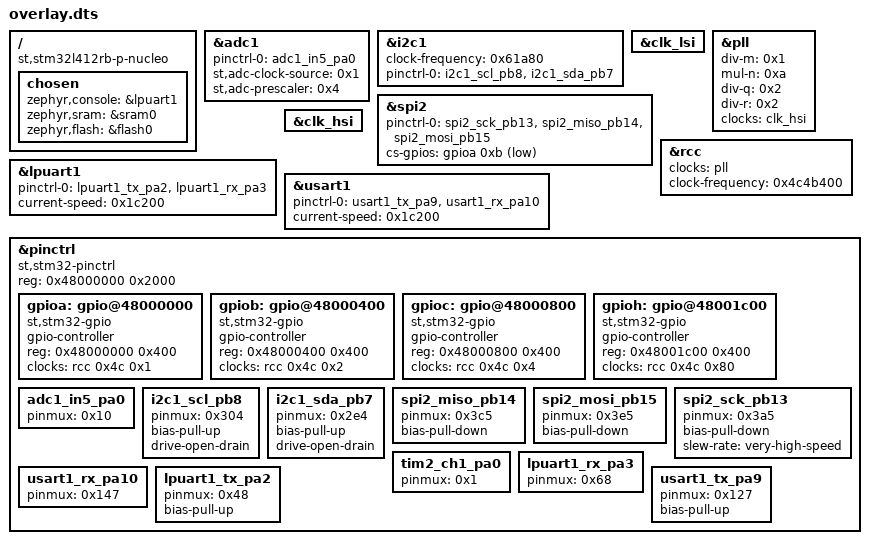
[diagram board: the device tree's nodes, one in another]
/ {
	compatible = "st,stm32l412rb-p-nucleo";
	chosen {
		zephyr,console = &lpuart1;
		zephyr,sram = &sram0;
		zephyr,flash = &flash0;
	};
};
&adc1{
	status = "okay";
	pinctrl-0 = < &adc1_in5_pa0 >;
	pinctrl-names = "default";
	st,adc-clock-source = < 0x1 >;
	st,adc-prescaler = < 0x4 >;
};
&i2c1{
	clock-frequency = < 0x61a80 >;
	status = "okay";
	pinctrl-0 = < &i2c1_scl_pb8 &i2c1_sda_pb7 >;
	pinctrl-names = "default";
};
&clk_lsi{
	status = "okay";
};
&pll{
	status = "okay";
	div-m = < 0x1 >;
	mul-n = < 0xa >;
	div-q = < 0x2 >;
	div-r = < 0x2 >;
	clocks = < &clk_hsi >;
};
&spi2{
	status = "okay";
	pinctrl-0 = < &spi2_sck_pb13 &spi2_miso_pb14 &spi2_mosi_pb15 >;
	pinctrl-names = "default";
	cs-gpios = < &gpioa 0xb 0x11 >;
};
&lpuart1{
	status = "okay";
	pinctrl-0 = < &lpuart1_tx_pa2 &lpuart1_rx_pa3 >;
	pinctrl-names = "default";
	current-speed = < 0x1c200 >;
};
&clk_hsi{
	status = "okay";
};
&rcc{
	clocks = < &pll >;
	clock-frequency = < 0x4c4b400 >;
};
&usart1{
	pinctrl-0 = < &usart1_tx_pa9 &usart1_rx_pa10 >;
	pinctrl-names = "default";
	current-speed = < 0x1c200 >;
};
&pinctrl{
	compatible = "st,stm32-pinctrl";
	#address-cells = < 0x1 >;
	#size-cells = < 0x1 >;
	reg = < 0x48000000 0x2000 >;
	gpioa: gpio@48000000 {
		compatible = "st,stm32-gpio";
		gpio-controller;
		#gpio-cells = < 0x2 >;
		reg = < 0x48000000 0x400 >;
		clocks = < &rcc 0x4c 0x1 >;
	};
	gpiob: gpio@48000400 {
		compatible = "st,stm32-gpio";
		gpio-controller;
		#gpio-cells = < 0x2 >;
		reg = < 0x48000400 0x400 >;
		clocks = < &rcc 0x4c 0x2 >;
	};
	gpioc: gpio@48000800 {
		compatible = "st,stm32-gpio";
		gpio-controller;
		#gpio-cells = < 0x2 >;
		reg = < 0x48000800 0x400 >;
		clocks = < &rcc 0x4c 0x4 >;
	};
	gpioh: gpio@48001c00 {
		compatible = "st,stm32-gpio";
		gpio-controller;
		#gpio-cells = < 0x2 >;
		reg = < 0x48001c00 0x400 >;
		clocks = < &rcc 0x4c 0x80 >;
	};
	adc1_in5_pa0: adc1_in5_pa0 {
		pinmux = < 0x10 >;
	};
	i2c1_scl_pb8: i2c1_scl_pb8 {
		pinmux = < 0x304 >;
		bias-pull-up;
		drive-open-drain;
	};
	i2c1_sda_pb7: i2c1_sda_pb7 {
		pinmux = < 0x2e4 >;
		bias-pull-up;
		drive-open-drain;
	};
	spi2_miso_pb14: spi2_miso_pb14 {
		pinmux = < 0x3c5 >;
		bias-pull-down;
	};
	spi2_mosi_pb15: spi2_mosi_pb15 {
		pinmux = < 0x3e5 >;
		bias-pull-down;
	};
	spi2_sck_pb13: spi2_sck_pb13 {
		pinmux = < 0x3a5 >;
		bias-pull-down;
		slew-rate = "very-high-speed";
	};
	tim2_ch1_pa0: tim2_ch1_pa0 {
		pinmux = < 0x1 >;
	};
	lpuart1_rx_pa3: lpuart1_rx_pa3 {
		pinmux = < 0x68 >;
	};
	usart1_rx_pa10: usart1_rx_pa10 {
		pinmux = < 0x147 >;
	};
	lpuart1_tx_pa2: lpuart1_tx_pa2 {
		pinmux = < 0x48 >;
		bias-pull-up;
	};
	usart1_tx_pa9: usart1_tx_pa9 {
		pinmux = < 0x127 >;
		bias-pull-up;
	};
};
